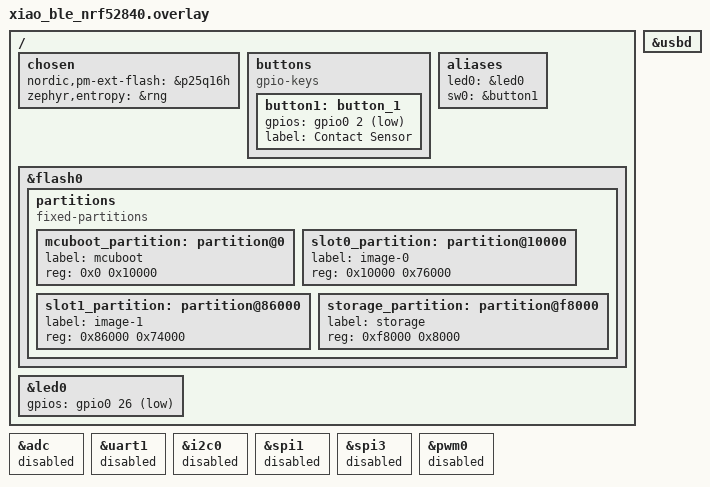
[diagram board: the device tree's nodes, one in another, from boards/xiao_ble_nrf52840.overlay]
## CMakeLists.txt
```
#
# Copyright (c) 2021 Nordic Semiconductor ASA
#
# SPDX-License-Identifier: LicenseRef-Nordic-5-Clause
#

cmake_minimum_required(VERSION 3.20.0)

find_package(Zephyr HINTS $ENV{ZEPHYR_BASE})

project(matter_contact_sensor)

# Enable GNU STD support.
include(${ZEPHYR_CONNECTEDHOMEIP_MODULE_DIR}/config/nrfconnect/app/enable-gnu-std.cmake)

# NORDIC SDK APP START

# Include all source files that are located in the Matter common directory.
include(${ZEPHYR_NRF_MODULE_DIR}/samples/matter/common/cmake/source_common.cmake)

# Include Data Model utils
include(${ZEPHYR_NRF_MODULE_DIR}/samples/matter/common/cmake/data_model.cmake)

include(${ZEPHYR_NRF_MODULE_DIR}/samples/matter/common/cmake/zap_helpers.cmake)
ncs_get_zap_parent_dir(ZAP_PARENT_DIR)

target_include_directories(app PRIVATE
  src
  ${ZAP_PARENT_DIR}
)

target_sources(app PRIVATE
  src/app_task.cpp
  src/main.cpp
)

ncs_configure_data_model()
# NORDIC SDK APP END
```

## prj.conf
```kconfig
#
# Copyright (c) 2021 Nordic Semiconductor ASA
#
# SPDX-License-Identifier: LicenseRef-Nordic-5-Clause
#

# This sample uses Kconfig.defaults to set options common for all
# samples. This file should contain only options specific for this sample
# or overrides of default values.

# Enable CHIP
CONFIG_CHIP=y
CONFIG_DK_LIBRARY=y
CONFIG_CHIP_PROJECT_CONFIG="src/chip_project_config.h"
CONFIG_CHIP_DEVICE_PRODUCT_NAME="Matter Contact Sensor"

# Configure ZAP file name
CONFIG_NCS_SAMPLE_MATTER_ZAP_FILE_PATH="${APPLICATION_CONFIG_DIR}/src/default_zap/contact_sensor.zap"

# 32768 == 0x8000 (example Product ID)
CONFIG_CHIP_DEVICE_PRODUCT_ID=32768
CONFIG_STD_CPP17=y

# Enable Matter pairing automatically on application start.
CONFIG_CHIP_ENABLE_PAIRING_AUTOSTART=y

# Enable Matter extended announcement and increase duration to 1 hour.
CONFIG_CHIP_BLE_EXT_ADVERTISING=y
CONFIG_CHIP_BLE_ADVERTISING_DURATION=60

# Add support for LEDs and buttons on Nordic development kits
CONFIG_DK_LIBRARY=y

# Bluetooth Low Energy configuration
CONFIG_BT_DEVICE_NAME="XiaoContact"
CONFIG_BT_DEVICE_NAME_MAX=18

# Enable system reset on fatal error
CONFIG_RESET_ON_FATAL_ERROR=y

# Disable all debug features
CONFIG_USE_SEGGER_RTT=n
CONFIG_SHELL=n
CONFIG_OPENTHREAD_SHELL=n
CONFIG_CHIP_LIB_SHELL=n
CONFIG_CONSOLE=n
CONFIG_UART_CONSOLE=n
CONFIG_SERIAL=n
CONFIG_LOG=n
CONFIG_LOG_MODE_MINIMAL=n
CONFIG_ASSERT_VERBOSE=n
CONFIG_ASSERT_NO_FILE_INFO=y
CONFIG_PRINTK=n
CONFIG_PRINTK_SYNC=n
CONFIG_THREAD_NAME=n
CONFIG_BOOT_BANNER=n

# Disable NFC onboarding
CONFIG_CHIP_NFC_ONBOARDING_PAYLOAD=n

# Enable Factory Data feature
CONFIG_CHIP_FACTORY_DATA=y
CONFIG_CHIP_FACTORY_DATA_BUILD=y

# Enable Watchdog
CONFIG_NCS_SAMPLE_MATTER_WATCHDOG=y

# Enable LTO to decrease the flash usage.
CONFIG_LTO=y
CONFIG_ISR_TABLES_LOCAL_DECLARATION=y

# GPIO for reed switch
CONFIG_GPIO=y
CONFIG_INPUT=y
CONFIG_INPUT_GPIO_KEYS=y

# Persistent Subscriptions
CONFIG_CHIP_PERSISTENT_SUBSCRIPTIONS=y

# Switch off LEDS
CONFIG_NCS_SAMPLE_MATTER_LEDS=n

# Configure Power Management
CONFIG_PM_DEVICE=y
CONFIG_RAM_POWER_DOWN_LIBRARY=y
CONFIG_POWEROFF=y

# Settings for ICD with LIT
CONFIG_OPENTHREAD_MTD=y
CONFIG_OPENTHREAD_NORDIC_LIBRARY_MTD=y

CONFIG_CHIP_ENABLE_ICD_SUPPORT=y
CONFIG_CHIP_ICD_LIT_SUPPORT=y

CONFIG_CHIP_ICD_IDLE_MODE_DURATION=900
CONFIG_CHIP_ICD_SLOW_POLL_INTERVAL=300000
CONFIG_CHIP_ICD_ACTIVE_MODE_DURATION=500
CONFIG_CHIP_ICD_ACTIVE_MODE_THRESHOLD=10000
CONFIG_CHIP_ICD_FAST_POLLING_INTERVAL=1000

CONFIG_CHIP_ICD_CLIENTS_PER_FABRIC=2
```

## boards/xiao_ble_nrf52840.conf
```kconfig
CONFIG_CHIP_FACTORY_DATA=n
CONFIG_CHIP_FACTORY_DATA_BUILD=n

CONFIG_BOOTLOADER_MCUBOOT=n
CONFIG_DFU_TARGET_MCUBOOT=n
CONFIG_CHIP_BOOTLOADER_MCUBOOT=n
CONFIG_CHIP_OTA_REQUESTOR=n
CONFIG_CHIP_BOOTLOADER_NONE=y
```

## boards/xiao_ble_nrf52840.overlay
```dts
/*
 * Adapted for Seeed Studio XIAO nRF52840 (non-Sense) Matter Contact Sensor
 * NCS SDK 3.2.x / UF2 bootloader via double-tap RST
 * Sources: Seeed Wiki, Zephyr xiao_ble, Nordic contact_sensor
 */

#include <zephyr/dt-bindings/led/led.h>
#include <samples/matter/nrf52_partitions.dtsi>

 / {
	chosen {
		nordic,pm-ext-flash = &p25q16h;
		zephyr,entropy = &rng;
	};

	/* Contact sensor (reed switch to D0/P0.02 + GND) */
	buttons {
		compatible = "gpio-keys";

		button1: button_1 {
			gpios = <&gpio0 2 (GPIO_PULL_UP | GPIO_ACTIVE_LOW)>;
			label = "Contact Sensor";
		};
	};

	aliases {
		led0 = &led0;
		sw0 = &button1;
	};

	/* Flash partitions (UF2/MCUBoot compatible) */
	&flash0 {
		partitions {
			compatible = "fixed-partitions";
			#address-cells = <1>;
			#size-cells = <1>;

			mcuboot_partition: partition@0 {
				label = "mcuboot";
				reg = <0x0 0x10000>;
			};

			slot0_partition: partition@10000 {
				label = "image-0";
				reg = <0x10000 0x76000>;
			};

			slot1_partition: partition@86000 {
				label = "image-1";
				reg = <0x86000 0x74000>;
			};

			storage_partition: partition@f8000 {
				label = "storage";
				reg = <0xf8000 0x8000>;
			};
		};
	};

	/* Onboard LED (non-Sense RGB) */
	&led0 {
		gpios = <&gpio0 26 GPIO_ACTIVE_LOW>;  /* Red channel example */
	};
};

/* Disable unused for low power + UF2 stability */
&adc { status = "disabled"; };
&uart1 { status = "disabled"; };
&i2c0 { status = "disabled"; };
&spi1 { status = "disabled"; };
&spi3 { status = "disabled"; };
&pwm0 { status = "disabled"; };
&usbd { status = "okay"; };  /* Keep USB for UF2 */
```

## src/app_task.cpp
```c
/*
 * Contact Sensor for Seeed Xiao nRF52840 with Reed Switch on D0
 */

#include "app_task.h"

#include "app/matter_init.h"
#include "app/task_executor.h"
#include "board/board.h"
#include "lib/core/CHIPError.h"
#include <app-common/zap-generated/attributes/Accessors.h>
#include <app/clusters/boolean-state-server/CodegenIntegration.h>

#include <zephyr/logging/log.h>
#include <zephyr/drivers/gpio.h>

LOG_MODULE_DECLARE(app, CONFIG_CHIP_APP_LOG_LEVEL);

using namespace ::chip;
using namespace ::chip::app;
using namespace ::chip::DeviceLayer;

namespace {
    constexpr chip::EndpointId kContactSensorEndpointId = 1;

    /* D0 = P0.02 on Seeed Xiao nRF52840 */
    const struct gpio_dt_spec reed_gpio = {
    .port = DEVICE_DT_GET(DT_NODELABEL(gpio0)),
    .pin = 2,
    .dt_flags = GPIO_ACTIVE_LOW | GPIO_PULL_UP,
    };

} // namespace

static struct gpio_callback reed_cb_data;

static void ReedSwitchHandler(const struct device *dev, struct gpio_callback *cb, uint32_t pins)
{
    bool contact_detected = gpio_pin_get_dt(&reed_gpio) != 0;  // ACTIVE_LOW

    Nrf::PostTask([contact_detected] {
        auto *booleanState = Clusters::BooleanState::FindClusterOnEndpoint(kContactSensorEndpointId);
        if (booleanState != nullptr) {
            booleanState->SetStateValue(contact_detected);
            LOG_INF("Contact %s", contact_detected ? "DETECTED (closed)" : "OPEN");
        }
    });
}

CHIP_ERROR AppTask::Init()
{
    ReturnErrorOnFailure(Nrf::Matter::PrepareServer());

    if (!Nrf::GetBoard().Init(nullptr)) {
        LOG_ERR("Board init failed.");
        return CHIP_ERROR_INCORRECT_STATE;
    }

    ReturnErrorOnFailure(Nrf::Matter::RegisterEventHandler(Nrf::Board::DefaultMatterEventHandler, 0));

    /* Reed Switch Setup */
    if (!device_is_ready(reed_gpio.port)) {
        LOG_ERR("Reed switch GPIO not ready");
        return CHIP_ERROR_INCORRECT_STATE;
    }

    gpio_pin_configure_dt(&reed_gpio, GPIO_INPUT);
    gpio_init_callback(&reed_cb_data, ReedSwitchHandler, BIT(reed_gpio.pin));
    gpio_add_callback(reed_gpio.port, &reed_cb_data);
    gpio_pin_interrupt_configure_dt(&reed_gpio, GPIO_INT_EDGE_BOTH);

    /* Initial state */
    bool initial_state = gpio_pin_get_dt(&reed_gpio) == 0;
    auto *booleanState = Clusters::BooleanState::FindClusterOnEndpoint(kContactSensorEndpointId);
    if (booleanState) {
        booleanState->SetStateValue(initial_state);
    }

    ReturnErrorOnFailure(Nrf::Matter::StartServer());

    LOG_INF("Matter Contact Sensor ready - Reed on D0");
    return CHIP_NO_ERROR;
}

CHIP_ERROR AppTask::StartApp()
{
    ReturnErrorOnFailure(Init());

    while (true) {
        Nrf::DispatchNextTask();
    }

    return CHIP_NO_ERROR;
}
```

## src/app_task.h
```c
/*
 * App Task header for Contact Sensor
 */

#pragma once

#include "board/board.h"

#include <platform/CHIPDeviceLayer.h>

class AppTask {
public:
    static AppTask &Instance()
    {
        static AppTask sAppTask;
        return sAppTask;
    }

    CHIP_ERROR StartApp();

private:
    CHIP_ERROR Init();
};
```
